# MIK32 register map
Vendor: Mikron; Series: MIK32; File version: 1.0
Registers are 32-bit, read-write, reset 0x0 unless marked. A register's access mark holds for its fields unless they carry their own. Offsets are from the block's base; [hi:lo] are bit positions.

## GPIO_IRQ — Модуль формирования прерываний
Base 0x00084C00
0x00 STATE ro — Текущее состояние выводов линий после мультисплексоров. Номер бита соответсвует номеру канала.
0x04 LINE_MUX — Управление мультиплексорами. Каждый мультиплесор управляется своими 4 битами: Mux_0 – [3:0]; Mux_1 – [7:4]; Mux_2 – [11:8]; Mux_3 – [15:12]; Mux_4 – [19:16]; Mux_5– [23:20]; Mux_6 – [27:24]; Mux_7 – [31:28]
0x08 INTERRUPT — Текущее состояние прерываний. Номер бита соответсвует номеру канала.
0x0C ENABLE_SET — Регистр разрешения прерываний При чтении – текущее состояние разрешений прерываний. При записи «1» разрешает прерывание от соответствующего канала.
0x10 ENABLE_CLEAR — Регистр запрета прерываний При чтении – текущее состояние разрешений прерываний. При записи «1» запрещает прерывание от соответствующего канала
0x14 EDGE — Регистр типа прерываний. При чтении – текущий тип прерывания: «1» – по событию (фронт или спад), «0» – по уровню. Запись «1» – прерывание формируется по событию для соответствующего канала Запись «0» - не влияет
0x18 LEVEL reset 0xFF — Регистр типа прерываний. При чтении – текущий тип прерывания (инвертированный): «0» – по событию; «1» – по уровню. Запись «1» – прерывание формируется по уровню для соответствующего канала Запись «0» - не влияет
0x1C LEVEL_SET — Регистр выбора уровня / события прерываний. При чтении: «0» – прерывания формируются по спаду или уровню логического «0»; «1» – прерывания формируются по нарастающему фронту или уровню логической «1» Запись «1» – прерывание формируется по нарастающему фронту или уровню логической «1» для соответствующего канала
0x20 LEVEL_CLEAR — Регистр уровня / со-бытия прерываний. При чтении: «0» – прерывания формируются по спаду или уровню логического «0»; «1» – прерывания формируются по нарастающему фронту или уровню логической «1» Запись «1»– прерывание формируется по спаду или уровню логического «0» для соответствующего канала
0x24 ANY_EDGE_SET — Регистр прерываний по любому событию. Запись «1» – прерывание формируется по любому изменению соответствующего канала
0x28 ANY_EDGE_CLEAR — Регистр прерываний по любому событию. Запись «1» – прерывание не формируется по любому изменению соответствующего канала
0x2C CLEAR wo write-1-clears — Регистр сброса флагов прерываний по событию. Запись «1» – очищает флаг прерывания соответствующего канала

## DAC0 — Управление ЦАП
Base 0x00085000
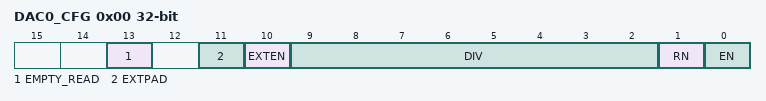
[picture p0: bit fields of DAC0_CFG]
0x00 DAC0_CFG — Регистр настойки ЦАП0
  [13] EMPTY_READ ro — Признак заполненности регистра DAC_VALUE
    0=Full (Значение, хранящееся в DAC_VALUE было сдвинуто в ЦАП, возможна запись следующего значения); 1=Empty (В регистре DAC_Value находится необработанное значение. Автоматически сбрасывается при записи в DAC_Value)
  [11] EXTPAD — Выбор источника внешнего опорного напряжения
    0=Calibrated_voltage_reference (Настраиваемый ИОН); 1=REF_DAC_PIN (Внешний вывод REF_ADC_DAC (PORT1_11))
  [10] EXTEN — Выбор источника опорного напряжения
    0=Internal (Встроенный); 1=External (Внешний)
  [9:2] DIV — Значение делителя тактового сигнала. Частота определяется как FЦАП=FIN/(DIV+1)
  [1] RN — Управление сбросом ЦАП, активный уровень «0»
  [0] EN — Управление питанием ЦАП
    0=Disable (Выключен); 1=Enable (Включен)
0x04 DAC0_VALUE wo — Входные данные для ЦАП0
  [11:0] VALUE rw — Входные данные для прерывания

## DAC1 — Управление ЦАП
Base 0x00085008
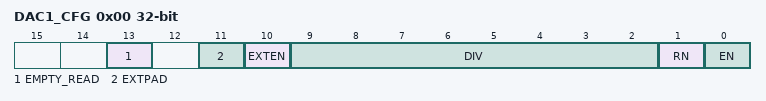
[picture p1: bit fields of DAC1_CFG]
0x00 DAC1_CFG — Регистр настойки ЦАП1
  [13] EMPTY_READ ro — Признак заполненности регистра DAC_VALUE
    0=Full (Значение, хранящееся в DAC_VALUE было сдвинуто в ЦАП, возможна запись следующего значения); 1=Empty (В регистре DAC_Value находится необработанное значение. Автоматически сбрасывается при записи в DAC_Value)
  [11] EXTPAD — Выбор источника внешнего опорного напряжения
    0=Calibrated_voltage_reference (Настраиваемый ИОН); 1=REF_DAC_PIN (Внешний вывод REF_ADC_DAC (PORT1_11))
  [10] EXTEN — Выбор источника опорного напряжения
    0=Internal (Встроенный); 1=External (Внешний)
  [9:2] DIV — Значение делителя тактового сигнала. Частота определяется как FЦАП=FIN/(DIV+1)
  [1] RN — Управление сбросом ЦАП, активный уровень «0»
  [0] EN — Управление питанием ЦАП
    0=Disable (Выключен); 1=Enable (Включен)
0x04 DAC1_VALUE wo — Входные данные для ЦАП1
  [11:0] VALUE rw — Входные данные для прерывания
